AUTOSAR XML (schema 4-2-2)
package /ASW_COM_Pkg
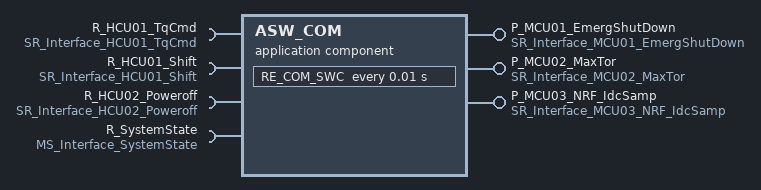
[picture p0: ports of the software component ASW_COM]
  application sw component type ASW_COM
    provide port P_MCU01_EmergShutDown: provided-interface=SR_Interface_MCU01_EmergShutDown
    provide port P_MCU02_MaxTor: provided-interface=SR_Interface_MCU02_MaxTor
    provide port P_MCU03_NRF_IdcSamp: provided-interface=SR_Interface_MCU03_NRF_IdcSamp
    4 x require port:
      R_HCU01_TqCmd: required-interface=SR_Interface_HCU01_TqCmd
      R_HCU01_Shift: required-interface=SR_Interface_HCU01_Shift
      R_HCU02_Poweroff: required-interface=SR_Interface_HCU02_Poweroff
      R_SystemState: mode-receiver-com-spec=enhanced-mode-api=false, required-interface=MS_Interface_SystemState
    behavior IB_ASW_COM
      timing event TE_RE_COM_SWC_10ms: start-on-event=RE_COM_SWC, period=0.01
      runnable RE_COM_SWC: mode-access-point=R_SystemState.MDG_SystemState
        data-read-access:
          access VA_READ_HCU01_TqCmd: accessed-variable=R_HCU01_TqCmd.DE_HCU01_TqCmd
          access VA_READ_HCU01_Shift: accessed-variable=R_HCU01_Shift.DE_HCU01_Shift
          access VA_READ_HCU02_Poweroff: accessed-variable=R_HCU02_Poweroff.DE_HCU02_Poweroff
        data-write-access:
          access VA_WRITE_MCU01_EmergShutDown: accessed-variable=P_MCU01_EmergShutDown.DE_MCU01_EmergShutDown
          access VA_WRITE_MCU02_MaxTor: accessed-variable=P_MCU02_MaxTor.DE_MCU02_MaxTor
          access VA_WRITE_MCU03_NRF_IdcSamp: accessed-variable=P_MCU03_NRF_IdcSamp.DE_MCU03_NRF_IdcSamp
package /COM_Interface
  6 x sender receiver interface:
    SR_Interface_MCU01_EmergShutDown
      data DE_MCU01_EmergShutDown: type=Idt_Boolean
    SR_Interface_MCU02_MaxTor
      data DE_MCU02_MaxTor: type=Idt_Float
    SR_Interface_MCU03_NRF_IdcSamp
      data DE_MCU03_NRF_IdcSamp: type=Idt_Float
    SR_Interface_HCU01_TqCmd
      data DE_HCU01_TqCmd: type=Idt_Float
    SR_Interface_HCU01_Shift
      data DE_HCU01_Shift: type=Idt_Uint8
    SR_Interface_HCU02_Poweroff: is-service=true
      data DE_HCU02_Poweroff: type=Idt_Boolean, alive-timeout=0.3
  mode switch interface MS_Interface_SystemState
    mode group MG_SystemState: type=MDG_SystemState
package /DataTypes
  impl type Idt_Boolean: category=VALUE
  impl type Idt_Float: category=VALUE
  impl type Idt_Uint8: category=VALUE
package /ModeDclr
  mode declaration group MDG_SystemState
    mode RUN
    mode SLEEP
